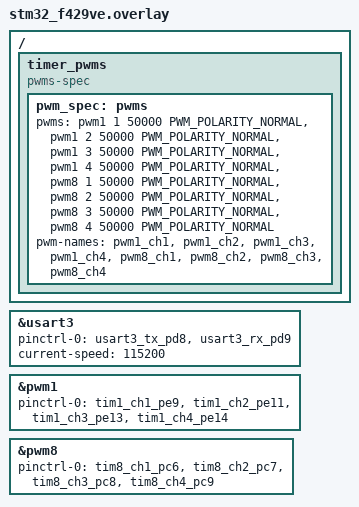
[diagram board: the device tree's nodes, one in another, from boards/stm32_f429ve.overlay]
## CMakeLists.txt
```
# SPDX-License-Identifier: Apache-2.0

cmake_minimum_required(VERSION 3.20.0)

set(BOARD stm32_f429ve)

find_package(Zephyr REQUIRED HINTS $ENV{ZEPHYR_BASE})
project(robot_chassis)

add_subdirectory(HAL)
add_subdirectory(Utilities)
include_directories(HAL/Inc)

file(GLOB application_sources Application/Src/*.cpp)
target_sources(app PRIVATE ${application_sources})
```

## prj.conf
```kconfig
CONFIG_STDOUT_CONSOLE=y
CONFIG_PRINTK=y
CONFIG_PWM=y
CONFIG_LOG=y
CONFIG_LOG_PRINTK=y
CONFIG_LOG_MODE_IMMEDIATE=y
CONFIG_PWM_LOG_LEVEL_DBG=y

CONFIG_NEWLIB_LIBC=y

CONFIG_CPLUSPLUS=y
CONFIG_LIB_CPLUSPLUS=y
```

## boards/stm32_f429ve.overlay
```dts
/*
 * SPDX-License-Identifier: Apache-2.0
 *
 * Copyright (c) 2022 STMicroelectronics
 */

/ {
    timer_pwms{
		compatible = "pwms-spec";
		pwm_spec: pwms {
			pwms = <&pwm1 1 50000 PWM_POLARITY_NORMAL>,
				   <&pwm1 2 50000 PWM_POLARITY_NORMAL>,
                   <&pwm1 3 50000 PWM_POLARITY_NORMAL>,
                   <&pwm1 4 50000 PWM_POLARITY_NORMAL>,
                   <&pwm8 1 50000 PWM_POLARITY_NORMAL>,
				   <&pwm8 2 50000 PWM_POLARITY_NORMAL>,
                   <&pwm8 3 50000 PWM_POLARITY_NORMAL>,
                   <&pwm8 4 50000 PWM_POLARITY_NORMAL>;
			pwm-names = "pwm1_ch1", "pwm1_ch2", "pwm1_ch3", "pwm1_ch4",
                        "pwm8_ch1", "pwm8_ch2", "pwm8_ch3", "pwm8_ch4";
		};
	};
};

&usart3 {
	pinctrl-0 = <&usart3_tx_pd8 &usart3_rx_pd9>;
	pinctrl-names = "default";
	current-speed = <115200>;
	status = "okay";
};

&pwm1 {
	status = "okay";
	pinctrl-0 = <&tim1_ch1_pe9 &tim1_ch2_pe11 &tim1_ch3_pe13 &tim1_ch4_pe14>;
	pinctrl-names = "default";
};

&pwm8 {
	status = "okay";
	pinctrl-0 = <&tim8_ch1_pc6 &tim8_ch2_pc7 &tim8_ch3_pc8 &tim8_ch4_pc9>;
	pinctrl-names = "default";
};
```

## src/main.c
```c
/*
 * Copyright (c) 2016 Intel Corporation
 * Copyright (c) 2020 Nordic Semiconductor ASA
 *
 * SPDX-License-Identifier: Apache-2.0
 */

/**
 * @file Sample app to demonstrate PWM.
 */

#include <zephyr/zephyr.h>
#include <zephyr/sys/printk.h>
#include <zephyr/device.h>
#include <zephyr/drivers/pwm.h>
#include <zephyr/drivers/gpio.h>

/* 1000 msec = 1 sec */
#define SLEEP_TIME_MS   1000

/* The devicetree node identifier for the "led0" alias. */
#define LED0_NODE DT_ALIAS(led0)

/*
 * A build error on this line means your board is unsupported.
 * See the sample documentation for information on how to fix this.
 */
static const struct gpio_dt_spec led = GPIO_DT_SPEC_GET(LED0_NODE, gpios);

void main(void)
{
	int ret;

	printk("system start...\n");

	if (!device_is_ready(led.port)) {
		return;
	}

	ret = gpio_pin_configure_dt(&led, GPIO_OUTPUT_ACTIVE);
	if (ret < 0) {
		return;
	}

	while (1) {
		ret = gpio_pin_toggle_dt(&led);
		if (ret < 0) {
			return;
		}
		k_msleep(SLEEP_TIME_MS);
	}
}
```
